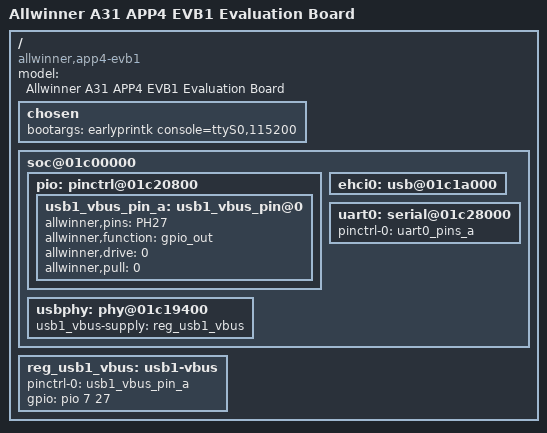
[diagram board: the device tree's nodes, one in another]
/*
 * Copyright 2014 Boris Brezillon
 *
 * Boris Brezillon <boris.brezillon@free-electrons.com>
 *
 * The code contained herein is licensed under the GNU General Public
 * License. You may obtain a copy of the GNU General Public License
 * Version 2 or later at the following locations:
 *
 * http://www.opensource.org/licenses/gpl-license.html
 * http://www.gnu.org/copyleft/gpl.html
 */

/dts-v1/;
/include/ "sun6i-a31.dtsi"
/include/ "sunxi-common-regulators.dtsi"

/ {
	model = "Allwinner A31 APP4 EVB1 Evaluation Board";
	compatible = "allwinner,app4-evb1", "allwinner,sun6i-a31";

	chosen {
		bootargs = "earlyprintk console=ttyS0,115200";
	};

	soc@01c00000 {
		pio: pinctrl@01c20800 {
			usb1_vbus_pin_a: usb1_vbus_pin@0 {
				allwinner,pins = "PH27";
				allwinner,function = "gpio_out";
				allwinner,drive = <0>;
				allwinner,pull = <0>;
			};
		};

		usbphy: phy@01c19400 {
			usb1_vbus-supply = <&reg_usb1_vbus>;
			status = "okay";
		};

		ehci0: usb@01c1a000 {
			status = "okay";
		};

		uart0: serial@01c28000 {
			pinctrl-names = "default";
			pinctrl-0 = <&uart0_pins_a>;
			status = "okay";
		};
	};

	reg_usb1_vbus: usb1-vbus {
		pinctrl-0 = <&usb1_vbus_pin_a>;
		gpio = <&pio 7 27 0>;
		status = "okay";
	};
};
